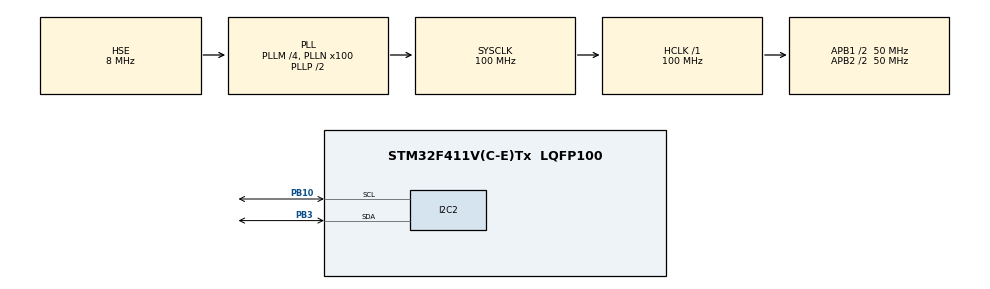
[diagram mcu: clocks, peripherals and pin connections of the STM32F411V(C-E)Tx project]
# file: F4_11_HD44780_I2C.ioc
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Mcu.Family=STM32F4
Mcu.Name=STM32F411V(C-E)Tx
Mcu.Package=LQFP100
NVIC.PriorityGroup=NVIC_PRIORITYGROUP_0
PA13.Mode=Serial_Wire
PA13.Signal=SYS_JTMS-SWDIO
PA14.Mode=Serial_Wire
PA14.Signal=SYS_JTCK-SWCLK
PB10.Mode=I2C
PB10.Signal=I2C2_SCL
PB3.Mode=I2C
PB3.Signal=I2C2_SDA
PH0\ -\ OSC_IN.GPIO_Label=PH0-OSC_IN
PH0\ -\ OSC_IN.Mode=HSE-External-Oscillator
PH0\ -\ OSC_IN.Signal=RCC_OSC_IN
PH1\ -\ OSC_OUT.GPIO_Label=PH1-OSC_OUT
PH1\ -\ OSC_OUT.Mode=HSE-External-Oscillator
PH1\ -\ OSC_OUT.Signal=RCC_OSC_OUT
ProjectManager.HeapSize=0x200
ProjectManager.StackSize=0x400
ProjectManager.TargetToolchain=STM32CubeIDE
RCC.48MHZClocksFreq_Value=25000000
RCC.AHBFreq_Value=100000000
RCC.APB1CLKDivider=RCC_HCLK_DIV2
RCC.APB1Freq_Value=50000000
RCC.APB1TimFreq_Value=100000000
RCC.APB2CLKDivider=RCC_HCLK_DIV2
RCC.APB2Freq_Value=50000000
RCC.APB2TimFreq_Value=100000000
RCC.CortexFreq_Value=100000000
RCC.HCLKFreq_Value=100000000
RCC.HSE_VALUE=8000000
RCC.HSI_VALUE=16000000
RCC.PLLI2SM=5
RCC.PLLI2SN=200
RCC.PLLM=4
RCC.PLLN=100
RCC.PLLQ=8
RCC.PLLSourceVirtual=RCC_PLLSOURCE_HSE
RCC.SYSCLKFreq_VALUE=100000000
RCC.SYSCLKSource=RCC_SYSCLKSOURCE_PLLCLK
RCC.VCOOutputFreq_Value=200000000
board=STM32F411E-DISCO

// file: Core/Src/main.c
/* USER CODE BEGIN Header */
/**
  ******************************************************************************
  * @file           : main.c
  * @brief          : Main program body
  ******************************************************************************
  * @attention
  *
  * Copyright (c) 2023 STMicroelectronics.
  * All rights reserved.
  *
  * This software is licensed under terms that can be found in the LICENSE file
  * in the root directory of this software component.
  * If no LICENSE file comes with this software, it is provided AS-IS.
  *
  ******************************************************************************
  */
/* USER CODE END Header */
#include "main.h"
#include "i2c.h"
#include "gpio.h"

/* USER CODE BEGIN Includes */
#include "lcd_i2c.h"
#include "stdio.h"
#include "stdbool.h"
/* USER CODE END Includes */

/* USER CODE BEGIN PV */
struct lcd_disp TEMP_LCD;
float temp1 = 10.3;
float temp2 = 35.2;
float temp3 = 10.5;
float temp4 = 40.1;
/* USER CODE END PV */

void SystemClock_Config(void);
/* USER CODE BEGIN PFP */
void LCD_init(struct lcd_disp * p_lcd_disp, uint8_t addr, bool backlight);
/* USER CODE END PFP */

int main(void)
{

  /* MCU Configuration--------------------------------------------------------*/

  /* Reset of all peripherals, Initializes the Flash interface and the Systick. */
  HAL_Init();

  /* Configure the system clock */
  SystemClock_Config();

  /* Initialize all configured peripherals */
  MX_GPIO_Init();
  MX_I2C2_Init();
  /* USER CODE BEGIN 2 */
  LCD_init(&TEMP_LCD, LCD_ADDRESS, true);
  /* USER CODE END 2 */

  /* Infinite loop */
  /* USER CODE BEGIN WHILE */
  while (1)
  {
	  temp1 += 0.1;
	  temp2 -= 0.1;
	  temp3 += 0.2;
	  temp4 += 0.3;
	  sprintf((char *) TEMP_LCD.f_line, "T1=%.1f  T2=%.1f", temp1, temp2);
	  sprintf((char *) TEMP_LCD.s_line, "T3=%.1f  T4=%.1f", temp3, temp4);
	  lcd_display(&TEMP_LCD);
	  HAL_Delay(1000UL);
    /* USER CODE END WHILE */

  }
}

void SystemClock_Config(void)
{
  RCC_OscInitTypeDef RCC_OscInitStruct = {0};
  RCC_ClkInitTypeDef RCC_ClkInitStruct = {0};

  /** Configure the main internal regulator output voltage
  */
  __HAL_RCC_PWR_CLK_ENABLE();
  __HAL_PWR_VOLTAGESCALING_CONFIG(PWR_REGULATOR_VOLTAGE_SCALE1);

  /** Initializes the RCC Oscillators according to the specified parameters
  * in the RCC_OscInitTypeDef structure.
  */
  RCC_OscInitStruct.OscillatorType = RCC_OSCILLATORTYPE_HSE;
  RCC_OscInitStruct.HSEState = RCC_HSE_ON;
  RCC_OscInitStruct.PLL.PLLState = RCC_PLL_ON;
  RCC_OscInitStruct.PLL.PLLSource = RCC_PLLSOURCE_HSE;
  RCC_OscInitStruct.PLL.PLLM = 4;
  RCC_OscInitStruct.PLL.PLLN = 100;
  RCC_OscInitStruct.PLL.PLLP = RCC_PLLP_DIV2;
  RCC_OscInitStruct.PLL.PLLQ = 8;
  if (HAL_RCC_OscConfig(&RCC_OscInitStruct) != HAL_OK)
  {
    Error_Handler();
  }

  /** Initializes the CPU, AHB and APB buses clocks
  */
  RCC_ClkInitStruct.ClockType = RCC_CLOCKTYPE_HCLK|RCC_CLOCKTYPE_SYSCLK
                              |RCC_CLOCKTYPE_PCLK1|RCC_CLOCKTYPE_PCLK2;
  RCC_ClkInitStruct.SYSCLKSource = RCC_SYSCLKSOURCE_PLLCLK;
  RCC_ClkInitStruct.AHBCLKDivider = RCC_SYSCLK_DIV1;
  RCC_ClkInitStruct.APB1CLKDivider = RCC_HCLK_DIV2;
  RCC_ClkInitStruct.APB2CLKDivider = RCC_HCLK_DIV2;

  if (HAL_RCC_ClockConfig(&RCC_ClkInitStruct, FLASH_LATENCY_3) != HAL_OK)
  {
    Error_Handler();
  }
}

/* USER CODE BEGIN 4 */
void LCD_init(struct lcd_disp * p_lcd_disp, uint8_t address, bool backlight)
{
	p_lcd_disp->addr = (address << 1);
	p_lcd_disp->bl = true;
	lcd_init(p_lcd_disp);
}
/* USER CODE END 4 */

void Error_Handler(void)
{
  __disable_irq();
  while (1)
  {
  }
}
